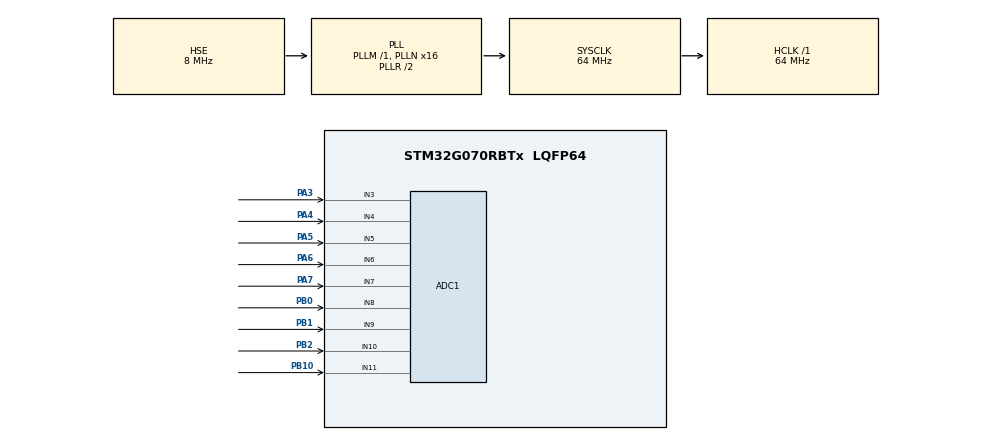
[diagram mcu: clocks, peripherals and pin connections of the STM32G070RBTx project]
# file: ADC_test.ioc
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ADC1.Channel-1\#ChannelRegularConversion=ADC_CHANNEL_3
ADC1.DMAContinuousRequests=ENABLE
ADC1.EOCSelection=ADC_EOC_SEQ_CONV
ADC1.ExternalTrigConv=ADC_EXTERNALTRIG_T3_TRGO
ADC1.NbrOfConversionFlag=1
ADC1.Rank-1\#ChannelRegularConversion=1
ADC1.SamplingTime-1\#ChannelRegularConversion=ADC_SAMPLINGTIME_COMMON_1
ADC1.SamplingTimeCommon1=ADC_SAMPLETIME_12CYCLES_5
ADC1.SamplingTimeCommon2=ADC_SAMPLETIME_12CYCLES_5
ADC1.master=1
Dma.ADC1.0.Direction=DMA_PERIPH_TO_MEMORY
Dma.ADC1.0.EventEnable=DISABLE
Dma.ADC1.0.Instance=DMA1_Channel1
Dma.ADC1.0.MemDataAlignment=DMA_MDATAALIGN_WORD
Dma.ADC1.0.MemInc=DMA_MINC_ENABLE
Dma.ADC1.0.Mode=DMA_CIRCULAR
Dma.ADC1.0.PeriphDataAlignment=DMA_PDATAALIGN_WORD
Dma.ADC1.0.PeriphInc=DMA_PINC_DISABLE
Dma.ADC1.0.Polarity=HAL_DMAMUX_REQ_GEN_RISING
Dma.ADC1.0.Priority=DMA_PRIORITY_HIGH
Dma.ADC1.0.RequestNumber=1
Dma.ADC1.0.SignalID=NONE
Dma.ADC1.0.SyncEnable=DISABLE
Dma.ADC1.0.SyncPolarity=HAL_DMAMUX_SYNC_NO_EVENT
Dma.ADC1.0.SyncRequestNumber=1
Dma.ADC1.0.SyncSignalID=NONE
Dma.Request0=ADC1
Mcu.Family=STM32G0
Mcu.Name=STM32G070RBTx
Mcu.Package=LQFP64
NVIC.DMA1_Channel1_IRQn=true\:0\:0\:false\:false\:true\:false\:true
NVIC.TIM3_IRQn=true\:0\:0\:false\:false\:true\:true\:true
PA13.Mode=Serial_Wire
PA13.Signal=SYS_SWDIO
PA14-BOOT0.Mode=Serial_Wire
PA14-BOOT0.Signal=SYS_SWCLK
PA3.Mode=IN3
PA3.Signal=ADC1_IN3
PA4.Mode=IN4
PA4.Signal=ADC1_IN4
PA5.Mode=IN5
PA5.Signal=ADC1_IN5
PA6.Mode=IN6
PA6.Signal=ADC1_IN6
PA7.Mode=IN7
PA7.Signal=ADC1_IN7
PB0.Mode=IN8
PB0.Signal=ADC1_IN8
PB1.Mode=IN9
PB1.Signal=ADC1_IN9
PB10.Mode=IN11
PB10.Signal=ADC1_IN11
PB2.Mode=IN10
PB2.Signal=ADC1_IN10
PC14-OSC32_IN\ (PC14).Mode=LSE-External-Oscillator
PC14-OSC32_IN\ (PC14).Signal=RCC_OSC32_IN
PC15-OSC32_OUT\ (PC15).Mode=LSE-External-Oscillator
PC15-OSC32_OUT\ (PC15).Signal=RCC_OSC32_OUT
PF0-OSC_IN\ (PF0).Mode=HSE-External-Oscillator
PF0-OSC_IN\ (PF0).Signal=RCC_OSC_IN
PF1-OSC_OUT\ (PF1).Mode=HSE-External-Oscillator
PF1-OSC_OUT\ (PF1).Signal=RCC_OSC_OUT
ProjectManager.HeapSize=0x200
ProjectManager.StackSize=0x400
ProjectManager.TargetToolchain=MDK-ARM V5
RCC.ADCFreq_Value=64000000
RCC.AHBFreq_Value=64000000
RCC.CortexFreq_Value=64000000
RCC.EXTERNAL_CLOCK_VALUE=48000
RCC.HCLKFreq_Value=64000000
RCC.HSE_VALUE=8000000
RCC.HSI_VALUE=16000000
RCC.PLLN=16
RCC.PLLSourceVirtual=RCC_PLLSOURCE_HSE
RCC.SYSCLKFreq_VALUE=64000000
RCC.SYSCLKSource=RCC_SYSCLKSOURCE_PLLCLK
RCC.VCOOutputFreq_Value=128000000
TIM3.Period=250-1
TIM3.Prescaler=64-1
TIM3.TIM_MasterOutputTrigger=TIM_TRGO_UPDATE
VP_TIM3_VS_ClockSourceINT.Mode=Internal
board=custom

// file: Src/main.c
/* USER CODE BEGIN Header */
/**
  ******************************************************************************
  * @file           : main.c
  * @brief          : Main program body
  ******************************************************************************
  * @attention
  *
  * <h2><center>&copy; Copyright (c) 2022 STMicroelectronics.
  * All rights reserved.</center></h2>
  *
  * This software component is licensed by ST under BSD 3-Clause license,
  * the "License"; You may not use this file except in compliance with the
  * License. You may obtain a copy of the License at:
  *                        opensource.org/licenses/BSD-3-Clause
  *
  ******************************************************************************
  */
/* USER CODE END Header */

#include "main.h"

ADC_HandleTypeDef hadc1;
DMA_HandleTypeDef hdma_adc1;

TIM_HandleTypeDef htim3;

void SystemClock_Config(void);
static void MX_GPIO_Init(void);
static void MX_DMA_Init(void);
static void MX_ADC1_Init(void);
static void MX_TIM3_Init(void);

/* USER CODE BEGIN 0 */
uint32_t adc_array[9];
/* USER CODE END 0 */

int main(void)
{

  /* MCU Configuration--------------------------------------------------------*/

  /* Reset of all peripherals, Initializes the Flash interface and the Systick. */
  HAL_Init();

  /* Configure the system clock */
  SystemClock_Config();

  /* Initialize all configured peripherals */
  MX_GPIO_Init();
  MX_DMA_Init();
  MX_ADC1_Init();
  MX_TIM3_Init();
  /* USER CODE BEGIN 2 */
	HAL_TIM_Base_Start(&htim3);

	HAL_ADCEx_Calibration_Start(&hadc1);
	HAL_ADC_Start_DMA(&hadc1,adc_array,9);

  /* USER CODE END 2 */

  /* Infinite loop */
  while (1)
  {

  }
}

void SystemClock_Config(void)
{
  RCC_OscInitTypeDef RCC_OscInitStruct = {0};
  RCC_ClkInitTypeDef RCC_ClkInitStruct = {0};
  RCC_PeriphCLKInitTypeDef PeriphClkInit = {0};

  /** Configure the main internal regulator output voltage
  */
  HAL_PWREx_ControlVoltageScaling(PWR_REGULATOR_VOLTAGE_SCALE1);
  /** Initializes the CPU, AHB and APB busses clocks
  */
  RCC_OscInitStruct.OscillatorType = RCC_OSCILLATORTYPE_HSE;
  RCC_OscInitStruct.HSEState = RCC_HSE_ON;
  RCC_OscInitStruct.PLL.PLLState = RCC_PLL_ON;
  RCC_OscInitStruct.PLL.PLLSource = RCC_PLLSOURCE_HSE;
  RCC_OscInitStruct.PLL.PLLM = RCC_PLLM_DIV1;
  RCC_OscInitStruct.PLL.PLLN = 16;
  RCC_OscInitStruct.PLL.PLLP = RCC_PLLP_DIV2;
  RCC_OscInitStruct.PLL.PLLR = RCC_PLLR_DIV2;
  if (HAL_RCC_OscConfig(&RCC_OscInitStruct) != HAL_OK)
  {
    Error_Handler();
  }
  /** Initializes the CPU, AHB and APB busses clocks
  */
  RCC_ClkInitStruct.ClockType = RCC_CLOCKTYPE_HCLK|RCC_CLOCKTYPE_SYSCLK
                              |RCC_CLOCKTYPE_PCLK1;
  RCC_ClkInitStruct.SYSCLKSource = RCC_SYSCLKSOURCE_PLLCLK;
  RCC_ClkInitStruct.AHBCLKDivider = RCC_SYSCLK_DIV1;
  RCC_ClkInitStruct.APB1CLKDivider = RCC_HCLK_DIV1;

  if (HAL_RCC_ClockConfig(&RCC_ClkInitStruct, FLASH_LATENCY_2) != HAL_OK)
  {
    Error_Handler();
  }
  /** Initializes the peripherals clocks
  */
  PeriphClkInit.PeriphClockSelection = RCC_PERIPHCLK_ADC;
  PeriphClkInit.AdcClockSelection = RCC_ADCCLKSOURCE_SYSCLK;
  if (HAL_RCCEx_PeriphCLKConfig(&PeriphClkInit) != HAL_OK)
  {
    Error_Handler();
  }
}

static void MX_ADC1_Init(void)
{

  ADC_ChannelConfTypeDef sConfig = {0};

  /** Configure the global features of the ADC (Clock, Resolution, Data Alignment and number of conversion)
  */
  hadc1.Instance = ADC1;
  hadc1.Init.ClockPrescaler = ADC_CLOCK_SYNC_PCLK_DIV2;
  hadc1.Init.Resolution = ADC_RESOLUTION_12B;
  hadc1.Init.DataAlign = ADC_DATAALIGN_RIGHT;
  hadc1.Init.ScanConvMode = ADC_SCAN_DISABLE;
  hadc1.Init.EOCSelection = ADC_EOC_SEQ_CONV;
  hadc1.Init.LowPowerAutoWait = DISABLE;
  hadc1.Init.LowPowerAutoPowerOff = DISABLE;
  hadc1.Init.ContinuousConvMode = DISABLE;
  hadc1.Init.NbrOfConversion = 1;
  hadc1.Init.DiscontinuousConvMode = DISABLE;
  hadc1.Init.ExternalTrigConv = ADC_EXTERNALTRIG_T3_TRGO;
  hadc1.Init.ExternalTrigConvEdge = ADC_EXTERNALTRIGCONVEDGE_RISING;
  hadc1.Init.DMAContinuousRequests = ENABLE;
  hadc1.Init.Overrun = ADC_OVR_DATA_PRESERVED;
  hadc1.Init.SamplingTimeCommon1 = ADC_SAMPLETIME_12CYCLES_5;
  hadc1.Init.SamplingTimeCommon2 = ADC_SAMPLETIME_12CYCLES_5;
  hadc1.Init.OversamplingMode = DISABLE;
  hadc1.Init.TriggerFrequencyMode = ADC_TRIGGER_FREQ_HIGH;
  if (HAL_ADC_Init(&hadc1) != HAL_OK)
  {
    Error_Handler();
  }
  /** Configure Regular Channel
  */
  sConfig.Channel = ADC_CHANNEL_3;
  sConfig.Rank = ADC_REGULAR_RANK_1;
  sConfig.SamplingTime = ADC_SAMPLINGTIME_COMMON_1;
  if (HAL_ADC_ConfigChannel(&hadc1, &sConfig) != HAL_OK)
  {
    Error_Handler();
  }

}

static void MX_TIM3_Init(void)
{

  TIM_ClockConfigTypeDef sClockSourceConfig = {0};
  TIM_MasterConfigTypeDef sMasterConfig = {0};

  htim3.Instance = TIM3;
  htim3.Init.Prescaler = 64-1;
  htim3.Init.CounterMode = TIM_COUNTERMODE_UP;
  htim3.Init.Period = 250-1;
  htim3.Init.ClockDivision = TIM_CLOCKDIVISION_DIV1;
  htim3.Init.AutoReloadPreload = TIM_AUTORELOAD_PRELOAD_DISABLE;
  if (HAL_TIM_Base_Init(&htim3) != HAL_OK)
  {
    Error_Handler();
  }
  sClockSourceConfig.ClockSource = TIM_CLOCKSOURCE_INTERNAL;
  if (HAL_TIM_ConfigClockSource(&htim3, &sClockSourceConfig) != HAL_OK)
  {
    Error_Handler();
  }
  sMasterConfig.MasterOutputTrigger = TIM_TRGO_UPDATE;
  sMasterConfig.MasterSlaveMode = TIM_MASTERSLAVEMODE_DISABLE;
  if (HAL_TIMEx_MasterConfigSynchronization(&htim3, &sMasterConfig) != HAL_OK)
  {
    Error_Handler();
  }

}

static void MX_DMA_Init(void)
{
  /* DMA controller clock enable */
  __HAL_RCC_DMA1_CLK_ENABLE();

  /* DMA interrupt init */
  /* DMA1_Channel1_IRQn interrupt configuration */
  HAL_NVIC_SetPriority(DMA1_Channel1_IRQn, 0, 0);
  HAL_NVIC_EnableIRQ(DMA1_Channel1_IRQn);

}

static void MX_GPIO_Init(void)
{

  /* GPIO Ports Clock Enable */
  __HAL_RCC_GPIOC_CLK_ENABLE();
  __HAL_RCC_GPIOF_CLK_ENABLE();
  __HAL_RCC_GPIOA_CLK_ENABLE();
  __HAL_RCC_GPIOB_CLK_ENABLE();

}

void Error_Handler(void)
{
}

/************************ (C) COPYRIGHT STMicroelectronics *****END OF FILE****/
